# CTRL_MODULE_CORE register map
Vendor: Texas Instruments
Registers are 32-bit, access per field, reset 0x0 unless marked. A register's access mark holds for its fields unless they carry their own. Offsets are as the file gives them; [hi:lo] are bit positions; {n}, {i} and the like mark numbered series; 'fields as' and 'values as' point back to an identical list.

## CTRL_MODULE_CORE (part 2 of 5)
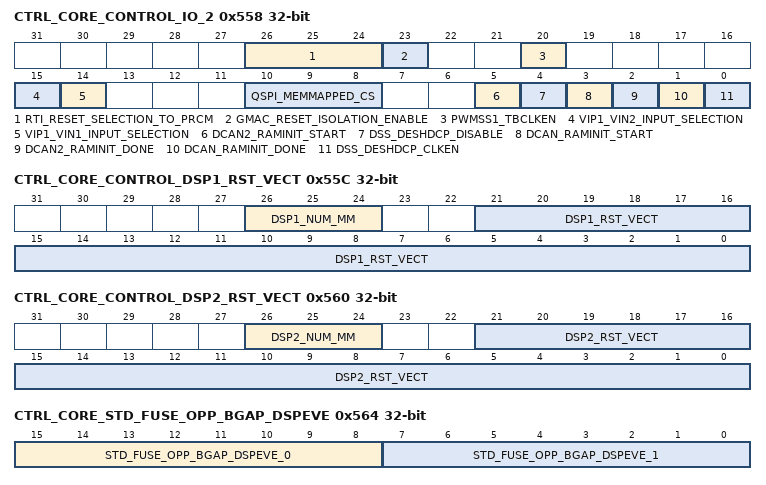
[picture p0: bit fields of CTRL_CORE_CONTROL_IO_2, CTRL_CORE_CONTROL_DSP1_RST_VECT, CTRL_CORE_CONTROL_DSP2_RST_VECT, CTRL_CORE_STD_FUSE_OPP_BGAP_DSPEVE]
0x558 CTRL_CORE_CONTROL_IO_2 — Register to configure some IP level signals
  [26:24] RTI_RESET_SELECTION_TO_PRCM rw — RTI reset mux select value. 0x0: RTI1 0x1: RTI2 0x2: RTI3 0x3: RTI4 0x4: RTI5
  [23] GMAC_RESET_ISOLATION_ENABLE rw — Reset isolation enable setting 0x0 = Reset is not isolated 0x1 = Reset is isolated
  [20] PWMSS1_TBCLKEN rw — PWMSS1 CLOCK ENABLE setting
  [15] VIP1_VIN2_INPUT_SELECTION rw — VIP1 vin2 input selection setting. 0x0: Input from pins selected. 0x1: Input from LVDSRX port2 selected.
  [14] VIP1_VIN1_INPUT_SELECTION rw — VIP1 vin1 input selection setting. 0x0: Input from pins selected. 0x1: Input from LVDSRX port1 selected.
  [10:8] QSPI_MEMMAPPED_CS rw — QSPI CS MAPPING setting. 0x0: The QSPI configuration registers are accessed 0x1: An external device connected to CS0 is accessed 0x2: An external device connected to CS1 is accessed 0x3: An external device connected to CS2 is accessed 0x4-0x7: An external device connected to CS3 is accessed
  [5] DCAN2_RAMINIT_START rw — DCAN2 RAM INIT START setting (SR1.0 Only). Reserved on SR2.0. To initialize DCAN2 RAM, the bit should be set to 0x1. It is not auto cleared by hardware. : If DCAN RAMINIT sequence needs to be redone, this bit should be first cleared and then set again.
  [4] DSS_DESHDCP_DISABLE rw — DSS DESHDCP DISABLE setting
  [3] DCAN_RAMINIT_START rw — DCAN RAM INIT START setting To initialize DCAN RAM, the bit should be set to 0x1. It is not auto cleared by hardware. : If DCAN RAMINIT sequence needs to be redone, this bit should be first cleared and then set again.: is called on SR1.0 devices.
  [2] DCAN2_RAMINIT_DONE rw — DCAN2 RAM INIT DONE status (SR1.0 Only). Reserved on SR2.0
  [1] DCAN_RAMINIT_DONE rw — DCAN RAM INIT DONE status: is called on SR1.0 devices.
  [0] DSS_DESHDCP_CLKEN rw — DSS DESHDCP CLOCK ENABLE setting
0x55C CTRL_CORE_CONTROL_DSP1_RST_VECT — Register for storing DSP1 reset vector
  [26:24] DSP1_NUM_MM rw — Number of DSP instances in the SoC 0x1 = 1 0x2 = 2
  [21:0] DSP1_RST_VECT rw — DSP1 reset vector address
0x560 CTRL_CORE_CONTROL_DSP2_RST_VECT — Register for storing DSP2 reset vector
  [26:24] DSP2_NUM_MM rw — Number of DSP instances in the SoC 0x1 = 1 0x2 = 2
  [21:0] DSP2_RST_VECT rw — DSP2 reset vector address
0x564 CTRL_CORE_STD_FUSE_OPP_BGAP_DSPEVE ro reset not defined — Trim values for DSPEVE associated bandgap. Contains TI Internal information, not intended for application use.
  [15:8] STD_FUSE_OPP_BGAP_DSPEVE_0 — Trim values for DSPEVE associated bandgap. Contains TI Internal information, not intended for application use.
  [7:0] STD_FUSE_OPP_BGAP_DSPEVE_1 — Trim values for DSPEVE associated bandgap. Contains TI Internal information, not intended for application use.
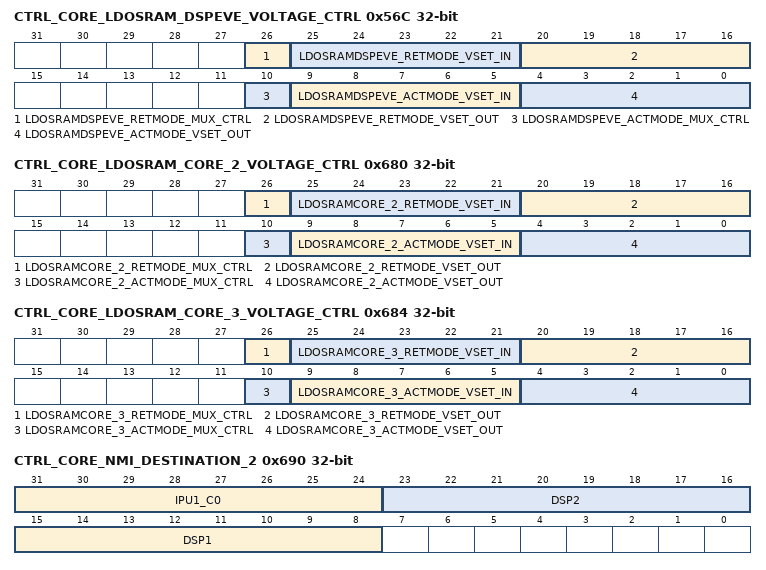
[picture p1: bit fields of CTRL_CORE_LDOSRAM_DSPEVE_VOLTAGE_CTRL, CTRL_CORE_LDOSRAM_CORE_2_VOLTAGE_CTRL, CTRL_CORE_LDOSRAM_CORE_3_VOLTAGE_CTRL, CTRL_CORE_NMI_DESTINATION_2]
0x56C CTRL_CORE_LDOSRAM_DSPEVE_VOLTAGE_CTRL — DSPEVE SRAM LDO Control register
  [26] LDOSRAMDSPEVE_RETMODE_MUX_CTRL rw — Override control of EFUSE Retention Mode Voltage value
    0=EFUSE (eFuse value is used); 1=OCP (Override value is used)
  [25:21] LDOSRAMDSPEVE_RETMODE_VSET_IN ro — EFUSE Retention Mode Voltage value (vset[9:5])
  [20:16] LDOSRAMDSPEVE_RETMODE_VSET_OUT rw — Override value for Retention Mode Voltage
  [10] LDOSRAMDSPEVE_ACTMODE_MUX_CTRL rw — Override control of EFUSE Active Mode Voltage value
    values as LDOSRAMDSPEVE_RETMODE_MUX_CTRL
  [9:5] LDOSRAMDSPEVE_ACTMODE_VSET_IN ro — EFUSE Active Mode Voltage value (vset[4:0])
  [4:0] LDOSRAMDSPEVE_ACTMODE_VSET_OUT rw — Override value for Active Mode Voltage value
0x5E0 CTRL_CORE_STD_FUSE_OPP_VMIN_DSPEVE_2 ro reset not defined — This register contains the AVS Class 0 voltage value for the vdd_dspeve voltage rail when running at OPP_NOM.
  [11:0] STD_FUSE_OPP_VMIN_DSPEVE_2 — AVS Class 0 voltage value for the vdd_dspeve voltage rail when running at OPP_NOM. To get the actual value in mV, the value read from this bit field must be converted to decimal value.
0x5E4 CTRL_CORE_STD_FUSE_OPP_VMIN_DSPEVE_3 ro reset not defined — This register contains the AVS Class 0 voltage value for the vdd_dspeve voltage rail when running at OPP_OD.
  [11:0] STD_FUSE_OPP_VMIN_DSPEVE_3 — AVS Class 0 voltage value for the vdd_dspeve voltage rail when running at OPP_OD. To get the actual value in mV, the value read from this bit field must be converted to decimal value.
0x5E8 CTRL_CORE_STD_FUSE_OPP_VMIN_DSPEVE_4 ro reset not defined — This register contains the AVS Class 0 voltage value for the vdd_dspeve voltage rail when running at OPP_HIGH.
  [11:0] STD_FUSE_OPP_VMIN_DSPEVE_4 — AVS Class 0 voltage value for the vdd_dspeve voltage rail when running at OPP_HIGH. To get the actual value in mV, the value read from this bit field must be converted to decimal value.
0x5EC CTRL_CORE_RC_OSC_FREQUENCY ro reset not defined — This register is used only on SR2.0 devices.
  [25:0] RC_OSC_CALIBRATION_VALUE — Used only on SR2.0 devices.
0x5F4 CTRL_CORE_STD_FUSE_OPP_VMIN_CORE_2 ro reset not defined — This register contains the AVS Class 0 voltage value for the vdd voltage rail when running at OPP_NOM.
  [11:0] STD_FUSE_OPP_VMIN_CORE_2 — AVS Class 0 voltage value for the vdd voltage rail when running at OPP_NOM. To get the actual value in mV, the value read from this bit field must be converted to decimal value.
0x680 CTRL_CORE_LDOSRAM_CORE_2_VOLTAGE_CTRL — CORE 2nd SRAM LDO Control register
  [26] LDOSRAMCORE_2_RETMODE_MUX_CTRL rw — Override control of EFUSE Retention Mode Voltage value
    values as CTRL_CORE_LDOSRAM_DSPEVE_VOLTAGE_CTRL.LDOSRAMDSPEVE_RETMODE_MUX_CTRL
  [25:21] LDOSRAMCORE_2_RETMODE_VSET_IN ro — EFUSE Retention Mode Voltage value (vset[9:5])
  [20:16] LDOSRAMCORE_2_RETMODE_VSET_OUT rw — Override value for Retention Mode Voltage
  [10] LDOSRAMCORE_2_ACTMODE_MUX_CTRL rw — Override control of EFUSE Active Mode Voltage value
    values as CTRL_CORE_LDOSRAM_DSPEVE_VOLTAGE_CTRL.LDOSRAMDSPEVE_RETMODE_MUX_CTRL
  [9:5] LDOSRAMCORE_2_ACTMODE_VSET_IN ro — EFUSE Active Mode Voltage value (vset[4:0])
  [4:0] LDOSRAMCORE_2_ACTMODE_VSET_OUT rw — Override value for Active Mode Voltage value
0x684 CTRL_CORE_LDOSRAM_CORE_3_VOLTAGE_CTRL — CORE 3rd SRAM LDO Control register
  [26] LDOSRAMCORE_3_RETMODE_MUX_CTRL rw — Override control of EFUSE Retention Mode Voltage value
    values as CTRL_CORE_LDOSRAM_DSPEVE_VOLTAGE_CTRL.LDOSRAMDSPEVE_RETMODE_MUX_CTRL
  [25:21] LDOSRAMCORE_3_RETMODE_VSET_IN ro — EFUSE Retention Mode Voltage value (vset[9:5])
  [20:16] LDOSRAMCORE_3_RETMODE_VSET_OUT rw — Override value for Retention Mode Voltage
  [10] LDOSRAMCORE_3_ACTMODE_MUX_CTRL rw — Override control of EFUSE Active Mode Voltage value
    values as CTRL_CORE_LDOSRAM_DSPEVE_VOLTAGE_CTRL.LDOSRAMDSPEVE_RETMODE_MUX_CTRL
  [9:5] LDOSRAMCORE_3_ACTMODE_VSET_IN ro — EFUSE Active Mode Voltage value (vset[4:0])
  [4:0] LDOSRAMCORE_3_ACTMODE_VSET_OUT rw — Override value for Active Mode Voltage value
0x68C CTRL_CORE_NMI_DESTINATION_1 rw — Register for routing NMI interrupt to respective cores
  [7:0] IPU1_C1 — Enable IPU1 CORE1 to receive the NMI interrupt 0x0 = NMI disabled 0x1 = NMI enabled
0x690 CTRL_CORE_NMI_DESTINATION_2 — Register for routing NMI interrupt to respective cores
  [31:24] IPU1_C0 rw — Enable IPU1 CORE0 to receive the NMI interrupt 0x0 = NMI disabled 0x1 = NMI enabled
  [23:16] DSP2 rw — Enable DSP2 to receive the NMI interrupt 0x0 = NMI disabled 0x1 = NMI enabled
  [15:8] DSP1 rw — Enable DSP1 to receive the NMI interrupt 0x0 = NMI disabled 0x1 = NMI enabled
{0x6A0+4i} CTRL_CORE_STD_FUSE_OPP_VDD_DSPEVE_{i} ro (i=0..4) — Standard Fuse OPP VDD_DSPEVE [{32i+31}:{32i}]. Register shows part of the chip eFuse configuration on the OCP interface. Reading at the address of one of these registers provides a direct view into a part of the eFuse chain.
  [31:0] STD_FUSE_OPP_VDD_DSPEVE_{i}
0x6B4 CTRL_CORE_CUST_FUSE_SWRV_7 ro — Customer Fuse keys. SWRV [31:0] (16 bits upper Redundant field) [FIELD A]. Register shows part of the chip eFuse configuration on the OCP interface. Reading at the address of one of these registers provides a direct view into a part of the eFuse chain.
  [31:0] CUST_FUSE_SWRV_7
0x6B8 CTRL_CORE_STD_FUSE_CALIBRATION_OVERRIDE_VALUE_0 ro — Standard Fuse Calibration override value [31:0]. Register shows part of the chip eFuse configuration on the OCP interface. Reading at the address of one of these registers provides a direct view into a part of the eFuse chain.
  [31:0] STD_FUSE_CALIBRATION_OVERRIDE_VALUE_0
0x6BC CTRL_CORE_STD_FUSE_CALIBRATION_OVERRIDE_VALUE_1 ro — Standard Fuse Calibration override value [63:32]. Register shows part of the chip eFuse configuration on the OCP interface. Reading at the address of one of these registers provides a direct view into a part of the eFuse chain.
  [31:0] STD_FUSE_CALIBRATION_OVERRIDE_VALUE_1
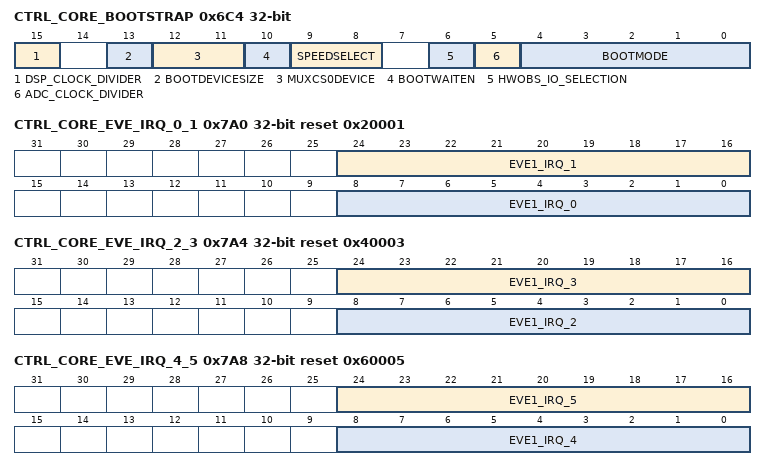
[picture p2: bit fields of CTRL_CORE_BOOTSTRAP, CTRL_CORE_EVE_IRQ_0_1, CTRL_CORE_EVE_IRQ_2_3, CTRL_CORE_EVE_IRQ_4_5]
0x6C4 CTRL_CORE_BOOTSTRAP ro — Register to view all the sysboot settings
  [15] DSP_CLOCK_DIVIDER — Divide factor for DSP clock
  [13] BOOTDEVICESIZE — Select the size of the flash device on CS0. 0x0: 8-bit 0x1: 16-bit
  [12:11] MUXCS0DEVICE — Select IC boot sequence to be executed from a multiplexed address and data device attached to CS0. 0x0: Non-muxed device attached 0x1: Addr-Data Mux device attached 0x2: Reserved 0x3: Reserved
  [10] BOOTWAITEN — Enable the monitoring on CS0 of the wait pin at IC reset release time for read accesses. 0x0: Wait pin is not monitored for read accesses 0x1: Wait pin is monitored for read accesses
  [9:8] SPEEDSELECT — Indicates the SYS_CLK1 frequency (from osc0). Note that the internal FUNC_32K_CLK is equal to SYS_CLK1/610, which is nominally 32.7869 kHz with 20 MHz clock. 0x0: Reserved 0x1: 20 MHz 0x2: 27 MHz 0x3: 19.2 MHz
  [6] HWOBS_IO_SELECTION
  [5] ADC_CLOCK_DIVIDER
  [4:0] BOOTMODE — SYSBOOT mode
0x794 CTRL_CORE_SEC_ERR_STATUS_FUNC_3 access not given
  [0] CRC_FW_ERROR — CRC firewall (access RW W1toClr)
    0=NO_EDMA_TC1_FW_ERROR (No error from firewall); 1=EDMA_TC1_FW_ERROR (Error from firewall)
0x79C CTRL_CORE_SEC_ERR_STATUS_DEBUG_3 access not given — Security Error Status functional Register
  [0] CRC_DBGFW_ERROR — CRC debug firewall (access RW W1toClr)
    values as CTRL_CORE_SEC_ERR_STATUS_FUNC_3.CRC_FW_ERROR
0x7A0 CTRL_CORE_EVE_IRQ_0_1 reset 0x20001
  [24:16] EVE1_IRQ_1 rw, [8:0] EVE1_IRQ_0 rw
0x7A4 CTRL_CORE_EVE_IRQ_2_3 reset 0x40003
  [24:16] EVE1_IRQ_3 rw, [8:0] EVE1_IRQ_2 rw
0x7A8 CTRL_CORE_EVE_IRQ_4_5 reset 0x60005
  [24:16] EVE1_IRQ_5 rw, [8:0] EVE1_IRQ_4 rw
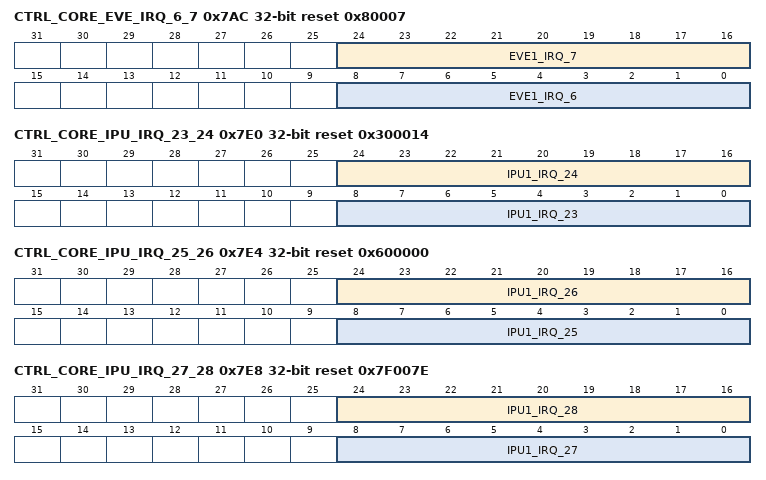
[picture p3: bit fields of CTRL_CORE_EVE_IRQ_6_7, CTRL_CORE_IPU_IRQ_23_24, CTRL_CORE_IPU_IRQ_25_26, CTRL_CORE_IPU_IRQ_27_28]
0x7AC CTRL_CORE_EVE_IRQ_6_7 reset 0x80007
  [24:16] EVE1_IRQ_7 rw, [8:0] EVE1_IRQ_6 rw
0x7E0 CTRL_CORE_IPU_IRQ_23_24 reset 0x300014
  [24:16] IPU1_IRQ_24 rw, [8:0] IPU1_IRQ_23 rw
0x7E4 CTRL_CORE_IPU_IRQ_25_26 reset 0x600000
  [24:16] IPU1_IRQ_26 rw, [8:0] IPU1_IRQ_25 rw
0x7E8 CTRL_CORE_IPU_IRQ_27_28 reset 0x7F007E
  [24:16] IPU1_IRQ_28 rw, [8:0] IPU1_IRQ_27 rw
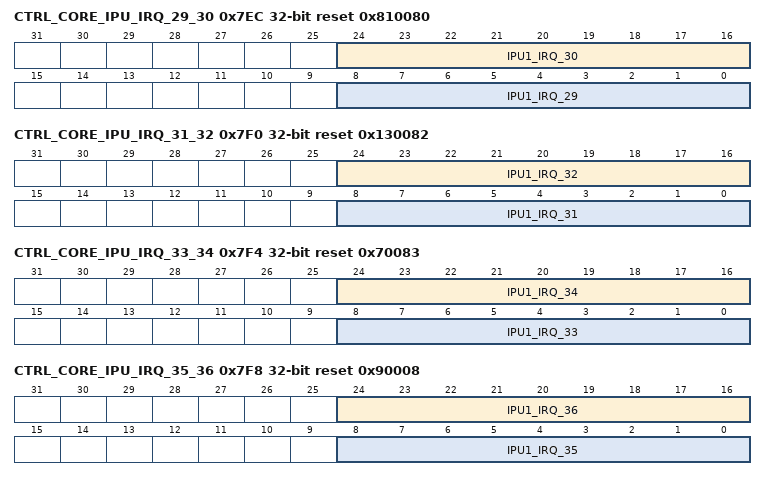
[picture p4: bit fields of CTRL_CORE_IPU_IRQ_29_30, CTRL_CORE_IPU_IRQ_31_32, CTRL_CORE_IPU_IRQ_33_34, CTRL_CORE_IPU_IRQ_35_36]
0x7EC CTRL_CORE_IPU_IRQ_29_30 reset 0x810080
  [24:16] IPU1_IRQ_30 rw, [8:0] IPU1_IRQ_29 rw
0x7F0 CTRL_CORE_IPU_IRQ_31_32 reset 0x130082
  [24:16] IPU1_IRQ_32 rw, [8:0] IPU1_IRQ_31 rw
0x7F4 CTRL_CORE_IPU_IRQ_33_34 reset 0x70083
  [24:16] IPU1_IRQ_34 rw, [8:0] IPU1_IRQ_33 rw
0x7F8 CTRL_CORE_IPU_IRQ_35_36 reset 0x90008
  [24:16] IPU1_IRQ_36 rw, [8:0] IPU1_IRQ_35 rw
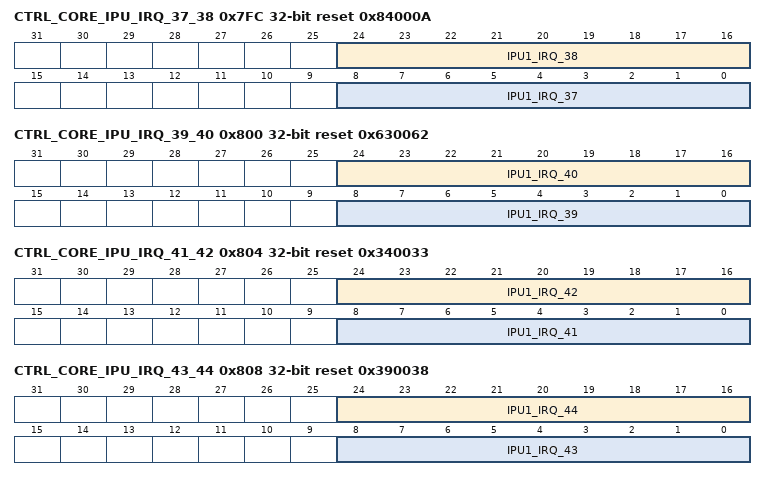
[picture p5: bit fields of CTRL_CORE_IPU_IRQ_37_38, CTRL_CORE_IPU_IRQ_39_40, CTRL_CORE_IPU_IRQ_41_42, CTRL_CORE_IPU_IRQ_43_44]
0x7FC CTRL_CORE_IPU_IRQ_37_38 reset 0x84000A
  [24:16] IPU1_IRQ_38 rw, [8:0] IPU1_IRQ_37 rw
0x800 CTRL_CORE_IPU_IRQ_39_40 reset 0x630062
  [24:16] IPU1_IRQ_40 rw, [8:0] IPU1_IRQ_39 rw
0x804 CTRL_CORE_IPU_IRQ_41_42 reset 0x340033
  [24:16] IPU1_IRQ_42 rw, [8:0] IPU1_IRQ_41 rw
0x808 CTRL_CORE_IPU_IRQ_43_44 reset 0x390038
  [24:16] IPU1_IRQ_44 rw, [8:0] IPU1_IRQ_43 rw
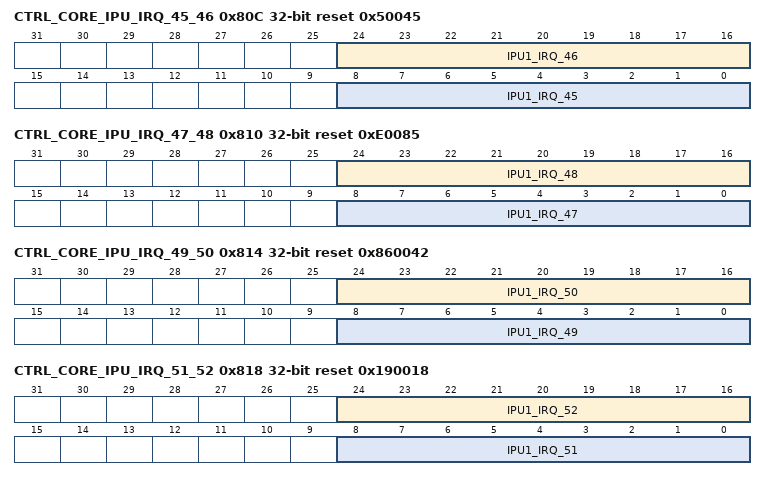
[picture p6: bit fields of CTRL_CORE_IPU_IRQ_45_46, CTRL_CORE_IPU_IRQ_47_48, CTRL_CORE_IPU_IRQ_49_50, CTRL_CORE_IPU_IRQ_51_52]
0x80C CTRL_CORE_IPU_IRQ_45_46 reset 0x50045
  [24:16] IPU1_IRQ_46 rw, [8:0] IPU1_IRQ_45 rw
0x810 CTRL_CORE_IPU_IRQ_47_48 reset 0xE0085
  [24:16] IPU1_IRQ_48 rw, [8:0] IPU1_IRQ_47 rw
0x814 CTRL_CORE_IPU_IRQ_49_50 reset 0x860042
  [24:16] IPU1_IRQ_50 rw, [8:0] IPU1_IRQ_49 rw
0x818 CTRL_CORE_IPU_IRQ_51_52 reset 0x190018
  [24:16] IPU1_IRQ_52 rw, [8:0] IPU1_IRQ_51 rw
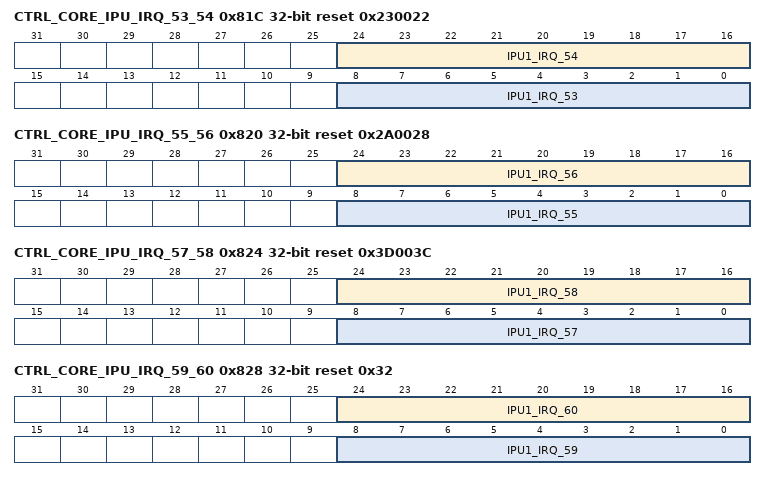
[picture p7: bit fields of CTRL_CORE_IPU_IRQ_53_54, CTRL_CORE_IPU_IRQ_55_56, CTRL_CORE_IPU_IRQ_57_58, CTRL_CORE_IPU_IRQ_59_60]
0x81C CTRL_CORE_IPU_IRQ_53_54 reset 0x230022
  [24:16] IPU1_IRQ_54 rw, [8:0] IPU1_IRQ_53 rw
0x820 CTRL_CORE_IPU_IRQ_55_56 reset 0x2A0028
  [24:16] IPU1_IRQ_56 rw, [8:0] IPU1_IRQ_55 rw
0x824 CTRL_CORE_IPU_IRQ_57_58 reset 0x3D003C
  [24:16] IPU1_IRQ_58 rw, [8:0] IPU1_IRQ_57 rw
0x828 CTRL_CORE_IPU_IRQ_59_60 reset 0x32
  [24:16] IPU1_IRQ_60 rw, [8:0] IPU1_IRQ_59 rw
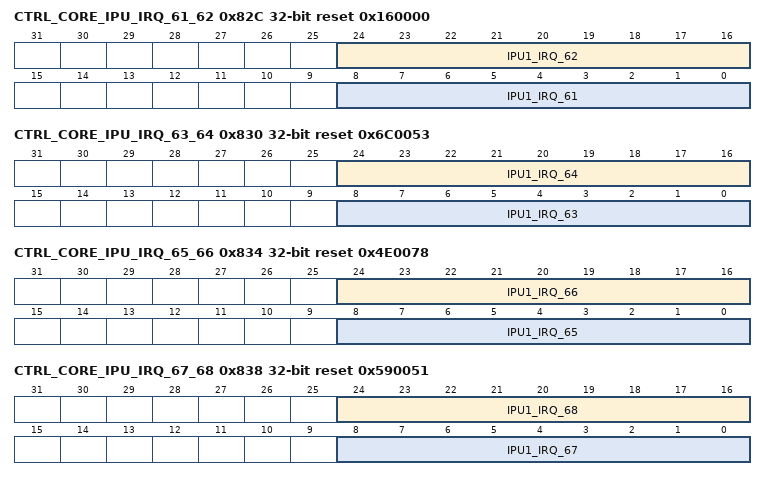
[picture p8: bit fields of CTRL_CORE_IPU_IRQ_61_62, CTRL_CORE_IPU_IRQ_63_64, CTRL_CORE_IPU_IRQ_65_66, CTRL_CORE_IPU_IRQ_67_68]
0x82C CTRL_CORE_IPU_IRQ_61_62 reset 0x160000
  [24:16] IPU1_IRQ_62 rw, [8:0] IPU1_IRQ_61 rw
0x830 CTRL_CORE_IPU_IRQ_63_64 reset 0x6C0053
  [24:16] IPU1_IRQ_64 rw, [8:0] IPU1_IRQ_63 rw
0x834 CTRL_CORE_IPU_IRQ_65_66 reset 0x4E0078
  [24:16] IPU1_IRQ_66 rw, [8:0] IPU1_IRQ_65 rw
0x838 CTRL_CORE_IPU_IRQ_67_68 reset 0x590051
  [24:16] IPU1_IRQ_68 rw, [8:0] IPU1_IRQ_67 rw
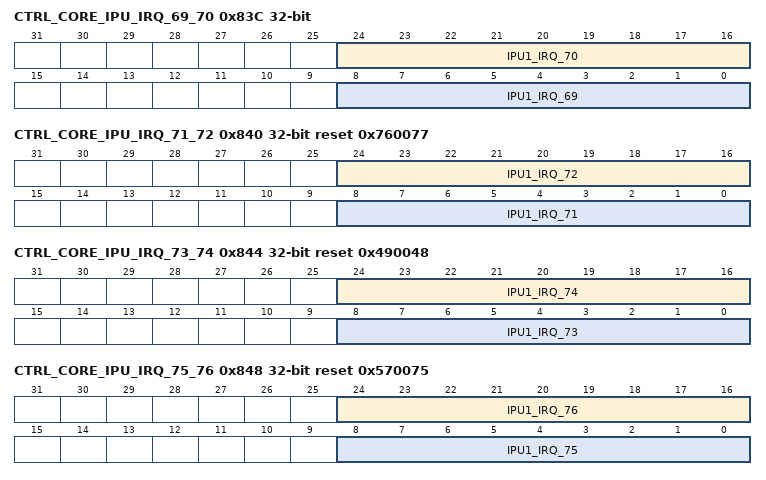
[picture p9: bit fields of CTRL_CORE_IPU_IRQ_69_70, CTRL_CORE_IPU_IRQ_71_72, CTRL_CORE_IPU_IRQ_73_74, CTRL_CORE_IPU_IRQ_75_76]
0x83C CTRL_CORE_IPU_IRQ_69_70
  [24:16] IPU1_IRQ_70 rw, [8:0] IPU1_IRQ_69 rw
0x840 CTRL_CORE_IPU_IRQ_71_72 reset 0x760077
  [24:16] IPU1_IRQ_72 rw, [8:0] IPU1_IRQ_71 rw
0x844 CTRL_CORE_IPU_IRQ_73_74 reset 0x490048
  [24:16] IPU1_IRQ_74 rw, [8:0] IPU1_IRQ_73 rw
0x848 CTRL_CORE_IPU_IRQ_75_76 reset 0x570075
  [24:16] IPU1_IRQ_76 rw, [8:0] IPU1_IRQ_75 rw
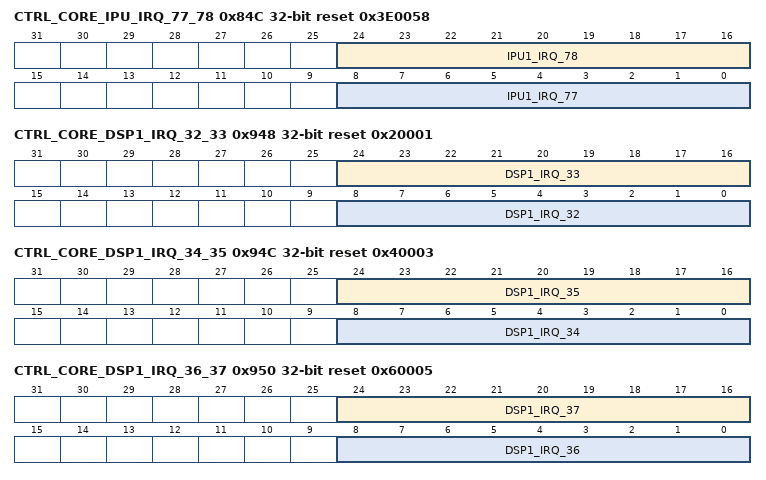
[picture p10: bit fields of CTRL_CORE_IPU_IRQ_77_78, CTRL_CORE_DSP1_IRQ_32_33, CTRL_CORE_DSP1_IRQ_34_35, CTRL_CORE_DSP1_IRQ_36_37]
0x84C CTRL_CORE_IPU_IRQ_77_78 reset 0x3E0058
  [24:16] IPU1_IRQ_78 rw, [8:0] IPU1_IRQ_77 rw
0x850 CTRL_CORE_IPU_IRQ_79_80 reset 0x3F
  [8:0] IPU1_IRQ_79 rw
0x948 CTRL_CORE_DSP1_IRQ_32_33 reset 0x20001
  [24:16] DSP1_IRQ_33 rw, [8:0] DSP1_IRQ_32 rw
0x94C CTRL_CORE_DSP1_IRQ_34_35 reset 0x40003
  [24:16] DSP1_IRQ_35 rw, [8:0] DSP1_IRQ_34 rw
0x950 CTRL_CORE_DSP1_IRQ_36_37 reset 0x60005
  [24:16] DSP1_IRQ_37 rw, [8:0] DSP1_IRQ_36 rw
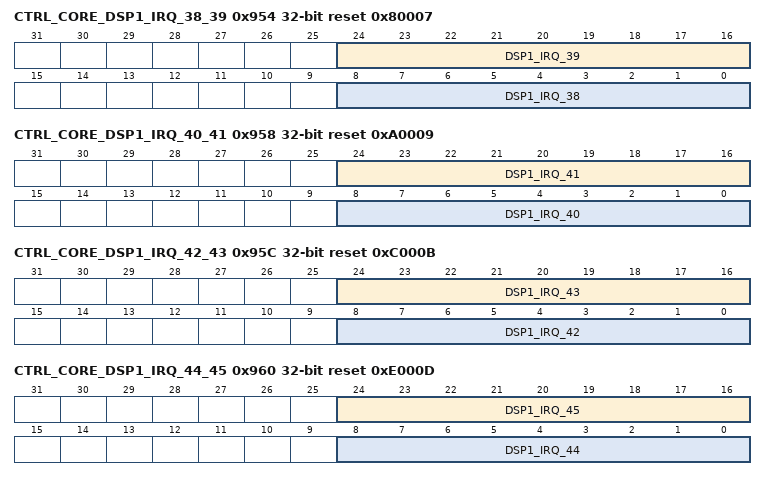
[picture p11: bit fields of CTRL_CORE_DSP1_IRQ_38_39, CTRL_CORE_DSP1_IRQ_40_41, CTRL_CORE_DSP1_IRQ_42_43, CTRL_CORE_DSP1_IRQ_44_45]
0x954 CTRL_CORE_DSP1_IRQ_38_39 reset 0x80007
  [24:16] DSP1_IRQ_39 rw, [8:0] DSP1_IRQ_38 rw
0x958 CTRL_CORE_DSP1_IRQ_40_41 reset 0xA0009
  [24:16] DSP1_IRQ_41 rw, [8:0] DSP1_IRQ_40 rw
0x95C CTRL_CORE_DSP1_IRQ_42_43 reset 0xC000B
  [24:16] DSP1_IRQ_43 rw, [8:0] DSP1_IRQ_42 rw
0x960 CTRL_CORE_DSP1_IRQ_44_45 reset 0xE000D
  [24:16] DSP1_IRQ_45 rw, [8:0] DSP1_IRQ_44 rw
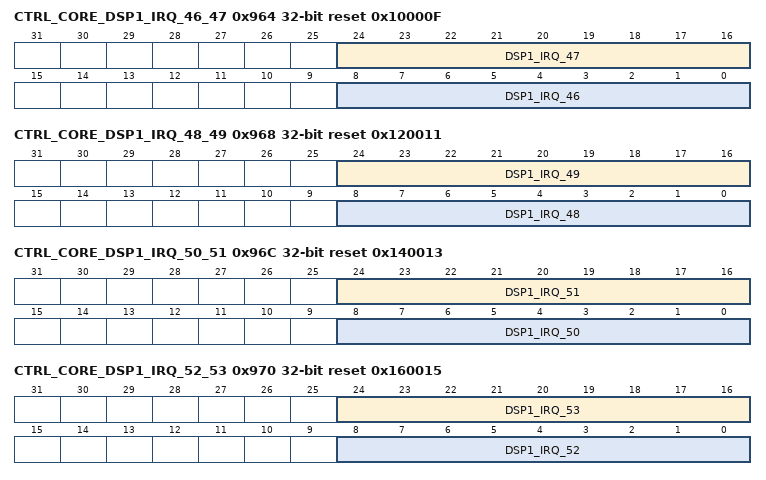
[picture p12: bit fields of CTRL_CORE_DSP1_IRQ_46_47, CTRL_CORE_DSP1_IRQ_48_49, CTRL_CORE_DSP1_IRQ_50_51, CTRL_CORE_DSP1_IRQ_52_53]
0x964 CTRL_CORE_DSP1_IRQ_46_47 reset 0x10000F
  [24:16] DSP1_IRQ_47 rw, [8:0] DSP1_IRQ_46 rw
0x968 CTRL_CORE_DSP1_IRQ_48_49 reset 0x120011
  [24:16] DSP1_IRQ_49 rw, [8:0] DSP1_IRQ_48 rw
0x96C CTRL_CORE_DSP1_IRQ_50_51 reset 0x140013
  [24:16] DSP1_IRQ_51 rw, [8:0] DSP1_IRQ_50 rw
0x970 CTRL_CORE_DSP1_IRQ_52_53 reset 0x160015
  [24:16] DSP1_IRQ_53 rw, [8:0] DSP1_IRQ_52 rw
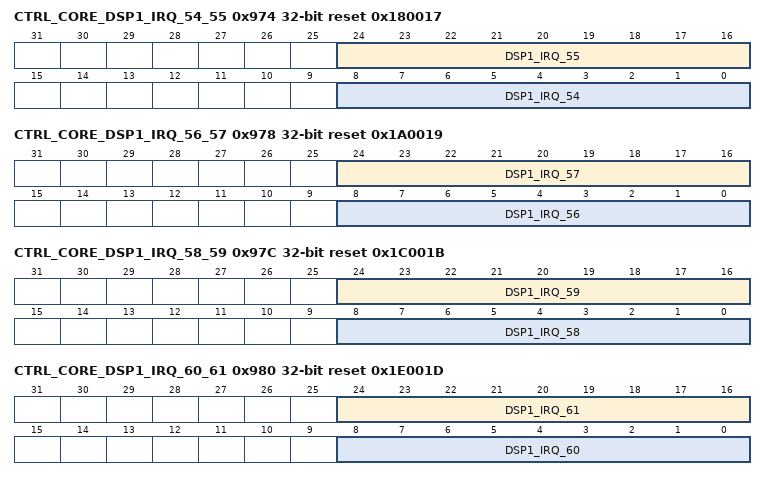
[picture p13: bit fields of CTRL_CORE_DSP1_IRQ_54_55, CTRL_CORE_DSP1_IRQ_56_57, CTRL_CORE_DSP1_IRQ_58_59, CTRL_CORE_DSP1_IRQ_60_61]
0x974 CTRL_CORE_DSP1_IRQ_54_55 reset 0x180017
  [24:16] DSP1_IRQ_55 rw, [8:0] DSP1_IRQ_54 rw
0x978 CTRL_CORE_DSP1_IRQ_56_57 reset 0x1A0019
  [24:16] DSP1_IRQ_57 rw, [8:0] DSP1_IRQ_56 rw
0x97C CTRL_CORE_DSP1_IRQ_58_59 reset 0x1C001B
  [24:16] DSP1_IRQ_59 rw, [8:0] DSP1_IRQ_58 rw
0x980 CTRL_CORE_DSP1_IRQ_60_61 reset 0x1E001D
  [24:16] DSP1_IRQ_61 rw, [8:0] DSP1_IRQ_60 rw
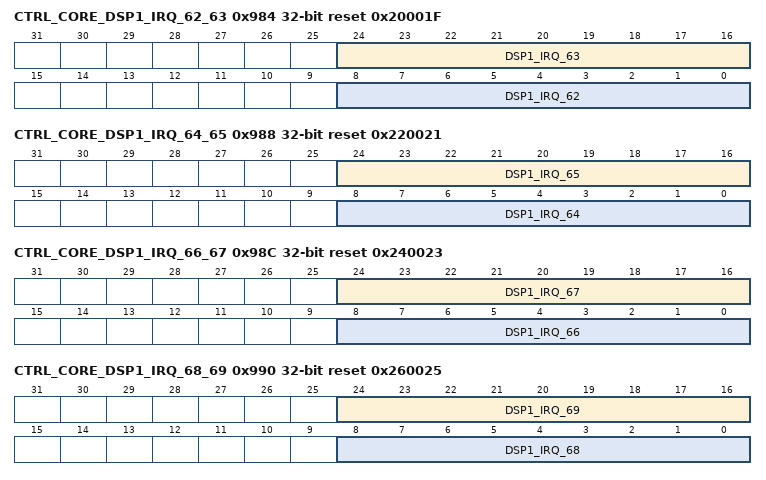
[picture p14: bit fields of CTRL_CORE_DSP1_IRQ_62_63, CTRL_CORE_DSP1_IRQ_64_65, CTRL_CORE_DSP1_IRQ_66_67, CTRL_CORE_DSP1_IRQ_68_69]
0x984 CTRL_CORE_DSP1_IRQ_62_63 reset 0x20001F
  [24:16] DSP1_IRQ_63 rw, [8:0] DSP1_IRQ_62 rw
0x988 CTRL_CORE_DSP1_IRQ_64_65 reset 0x220021
  [24:16] DSP1_IRQ_65 rw, [8:0] DSP1_IRQ_64 rw
0x98C CTRL_CORE_DSP1_IRQ_66_67 reset 0x240023
  [24:16] DSP1_IRQ_67 rw, [8:0] DSP1_IRQ_66 rw
0x990 CTRL_CORE_DSP1_IRQ_68_69 reset 0x260025
  [24:16] DSP1_IRQ_69 rw, [8:0] DSP1_IRQ_68 rw
0x994 CTRL_CORE_DSP1_IRQ_70_71 reset 0x280027
  [24:16] DSP1_IRQ_71 rw, [8:0] DSP1_IRQ_70 rw
0x998 CTRL_CORE_DSP1_IRQ_72_73 reset 0x2A0029
  [24:16] DSP1_IRQ_73 rw, [8:0] DSP1_IRQ_72 rw
0x99C CTRL_CORE_DSP1_IRQ_74_75 reset 0x2C002B
  [24:16] DSP1_IRQ_75 rw, [8:0] DSP1_IRQ_74 rw
0x9A0 CTRL_CORE_DSP1_IRQ_76_77 reset 0x2E002D
  [24:16] DSP1_IRQ_77 rw, [8:0] DSP1_IRQ_76 rw
0x9A4 CTRL_CORE_DSP1_IRQ_78_79 reset 0x30002F
  [24:16] DSP1_IRQ_79 rw, [8:0] DSP1_IRQ_78 rw
0x9A8 CTRL_CORE_DSP1_IRQ_80_81 reset 0x320031
  [24:16] DSP1_IRQ_81 rw, [8:0] DSP1_IRQ_80 rw
0x9AC CTRL_CORE_DSP1_IRQ_82_83 reset 0x340033
  [24:16] DSP1_IRQ_83 rw, [8:0] DSP1_IRQ_82 rw
0x9B0 CTRL_CORE_DSP1_IRQ_84_85 reset 0x360035
  [24:16] DSP1_IRQ_85 rw, [8:0] DSP1_IRQ_84 rw
0x9B4 CTRL_CORE_DSP1_IRQ_86_87 reset 0x380037
  [24:16] DSP1_IRQ_87 rw, [8:0] DSP1_IRQ_86 rw
0x9B8 CTRL_CORE_DSP1_IRQ_88_89 reset 0x3A0039
  [24:16] DSP1_IRQ_89 rw, [8:0] DSP1_IRQ_88 rw
0x9BC CTRL_CORE_DSP1_IRQ_90_91 reset 0x3C003B
  [24:16] DSP1_IRQ_91 rw, [8:0] DSP1_IRQ_90 rw
0x9C0 CTRL_CORE_DSP1_IRQ_92_93 reset 0x3E003D
  [24:16] DSP1_IRQ_93 rw, [8:0] DSP1_IRQ_92 rw
0x9C4 CTRL_CORE_DSP1_IRQ_94_95 reset 0x40003F
  [24:16] DSP1_IRQ_95 rw, [8:0] DSP1_IRQ_94 rw
0x9C8 CTRL_CORE_DSP2_IRQ_32_33 reset 0x20001
  [24:16] DSP2_IRQ_33 rw, [8:0] DSP2_IRQ_32 rw
0x9CC CTRL_CORE_DSP2_IRQ_34_35 reset 0x40003
  [24:16] DSP2_IRQ_35 rw, [8:0] DSP2_IRQ_34 rw
0x9D0 CTRL_CORE_DSP2_IRQ_36_37 reset 0x60005
  [24:16] DSP2_IRQ_37 rw, [8:0] DSP2_IRQ_36 rw
0x9D4 CTRL_CORE_DSP2_IRQ_38_39 reset 0x80007
  [24:16] DSP2_IRQ_39 rw, [8:0] DSP2_IRQ_38 rw
0x9D8 CTRL_CORE_DSP2_IRQ_40_41 reset 0xA0009
  [24:16] DSP2_IRQ_41 rw, [8:0] DSP2_IRQ_40 rw
0x9DC CTRL_CORE_DSP2_IRQ_42_43 reset 0xC000B
  [24:16] DSP2_IRQ_43 rw, [8:0] DSP2_IRQ_42 rw
0x9E0 CTRL_CORE_DSP2_IRQ_44_45 reset 0xE000D
  [24:16] DSP2_IRQ_45 rw, [8:0] DSP2_IRQ_44 rw
0x9E4 CTRL_CORE_DSP2_IRQ_46_47 reset 0x10000F
  [24:16] DSP2_IRQ_47 rw, [8:0] DSP2_IRQ_46 rw
0x9E8 CTRL_CORE_DSP2_IRQ_48_49 reset 0x120011
  [24:16] DSP2_IRQ_49 rw, [8:0] DSP2_IRQ_48 rw
0x9EC CTRL_CORE_DSP2_IRQ_50_51 reset 0x140013
  [24:16] DSP2_IRQ_51 rw, [8:0] DSP2_IRQ_50 rw
0x9F0 CTRL_CORE_DSP2_IRQ_52_53 reset 0x160015
  [24:16] DSP2_IRQ_53 rw, [8:0] DSP2_IRQ_52 rw
0x9F4 CTRL_CORE_DSP2_IRQ_54_55 reset 0x180017
  [24:16] DSP2_IRQ_55 rw, [8:0] DSP2_IRQ_54 rw
0x9F8 CTRL_CORE_DSP2_IRQ_56_57 reset 0x1A0019
  [24:16] DSP2_IRQ_57 rw, [8:0] DSP2_IRQ_56 rw
0x9FC CTRL_CORE_DSP2_IRQ_58_59 reset 0x1C001B
  [24:16] DSP2_IRQ_59 rw, [8:0] DSP2_IRQ_58 rw
0xA00 CTRL_CORE_DSP2_IRQ_60_61 reset 0x1E001D
  [24:16] DSP2_IRQ_61 rw, [8:0] DSP2_IRQ_60 rw
0xA04 CTRL_CORE_DSP2_IRQ_62_63 reset 0x20001F
  [24:16] DSP2_IRQ_63 rw, [8:0] DSP2_IRQ_62 rw
0xA08 CTRL_CORE_DSP2_IRQ_64_65 reset 0x220021
  [24:16] DSP2_IRQ_65 rw, [8:0] DSP2_IRQ_64 rw
0xA0C CTRL_CORE_DSP2_IRQ_66_67 reset 0x240023
  [24:16] DSP2_IRQ_67 rw, [8:0] DSP2_IRQ_66 rw
0xA10 CTRL_CORE_DSP2_IRQ_68_69 reset 0x260025
  [24:16] DSP2_IRQ_69 rw, [8:0] DSP2_IRQ_68 rw
0xA14 CTRL_CORE_DSP2_IRQ_70_71 reset 0x280027
  [24:16] DSP2_IRQ_71 rw, [8:0] DSP2_IRQ_70 rw
0xA18 CTRL_CORE_DSP2_IRQ_72_73 reset 0x2A0029
  [24:16] DSP2_IRQ_73 rw, [8:0] DSP2_IRQ_72 rw
0xA1C CTRL_CORE_DSP2_IRQ_74_75 reset 0x2C002B
  [24:16] DSP2_IRQ_75 rw, [8:0] DSP2_IRQ_74 rw
0xA20 CTRL_CORE_DSP2_IRQ_76_77 reset 0x2E002D
  [24:16] DSP2_IRQ_77 rw, [8:0] DSP2_IRQ_76 rw
0xA24 CTRL_CORE_DSP2_IRQ_78_79 reset 0x30002F
  [24:16] DSP2_IRQ_79 rw, [8:0] DSP2_IRQ_78 rw
0xA28 CTRL_CORE_DSP2_IRQ_80_81 reset 0x320031
  [24:16] DSP2_IRQ_81 rw, [8:0] DSP2_IRQ_80 rw
0xA2C CTRL_CORE_DSP2_IRQ_82_83 reset 0x340033
  [24:16] DSP2_IRQ_83 rw, [8:0] DSP2_IRQ_82 rw
0xA30 CTRL_CORE_DSP2_IRQ_84_85 reset 0x360035
  [24:16] DSP2_IRQ_85 rw, [8:0] DSP2_IRQ_84 rw
0xA34 CTRL_CORE_DSP2_IRQ_86_87 reset 0x380037
  [24:16] DSP2_IRQ_87 rw, [8:0] DSP2_IRQ_86 rw
0xA38 CTRL_CORE_DSP2_IRQ_88_89 reset 0x3A0039
  [24:16] DSP2_IRQ_89 rw, [8:0] DSP2_IRQ_88 rw
0xA3C CTRL_CORE_DSP2_IRQ_90_91 reset 0x3C003B
  [24:16] DSP2_IRQ_91 rw, [8:0] DSP2_IRQ_90 rw
0xA40 CTRL_CORE_DSP2_IRQ_92_93 reset 0x3E003D
  [24:16] DSP2_IRQ_93 rw, [8:0] DSP2_IRQ_92 rw
0xA44 CTRL_CORE_DSP2_IRQ_94_95 reset 0x40003F
  [24:16] DSP2_IRQ_95 rw, [8:0] DSP2_IRQ_94 rw
0xC78 CTRL_CORE_DMA_EDMA_DREQ_0_1 reset 0x20001
  [23:16] DMA_EDMA_DREQ_1_IRQ_1 rw, [7:0] DMA_EDMA_DREQ_0_IRQ_0 rw
0xC7C CTRL_CORE_DMA_EDMA_DREQ_2_3 reset 0x40003
  [23:16] DMA_EDMA_DREQ_3_IRQ_3 rw, [7:0] DMA_EDMA_DREQ_2_IRQ_2 rw
0xC80 CTRL_CORE_DMA_EDMA_DREQ_4_5 reset 0x60005
  [23:16] DMA_EDMA_DREQ_5_IRQ_5 rw, [7:0] DMA_EDMA_DREQ_4_IRQ_4 rw
0xC84 CTRL_CORE_DMA_EDMA_DREQ_6_7 reset 0x80007
  [23:16] DMA_EDMA_DREQ_7_IRQ_7 rw, [7:0] DMA_EDMA_DREQ_6_IRQ_6 rw
0xC88 CTRL_CORE_DMA_EDMA_DREQ_8_9 reset 0xA0009
  [23:16] DMA_EDMA_DREQ_9_IRQ_9 rw, [7:0] DMA_EDMA_DREQ_8_IRQ_8 rw
0xC8C CTRL_CORE_DMA_EDMA_DREQ_10_11 reset 0xC000B
  [23:16] DMA_EDMA_DREQ_11_IRQ_11 rw, [7:0] DMA_EDMA_DREQ_10_IRQ_10 rw
0xC90 CTRL_CORE_DMA_EDMA_DREQ_12_13 reset 0xE000D
  [23:16] DMA_EDMA_DREQ_13_IRQ_13 rw, [7:0] DMA_EDMA_DREQ_12_IRQ_12 rw
0xC94 CTRL_CORE_DMA_EDMA_DREQ_14_15 reset 0x10000F
  [23:16] DMA_EDMA_DREQ_15_IRQ_15 rw, [7:0] DMA_EDMA_DREQ_14_IRQ_14 rw
0xC98 CTRL_CORE_DMA_EDMA_DREQ_16_17 reset 0x120011
  [23:16] DMA_EDMA_DREQ_17_IRQ_17 rw, [7:0] DMA_EDMA_DREQ_16_IRQ_16 rw
0xC9C CTRL_CORE_DMA_EDMA_DREQ_18_19 reset 0x140013
  [23:16] DMA_EDMA_DREQ_19_IRQ_19 rw, [7:0] DMA_EDMA_DREQ_18_IRQ_18 rw
0xCA0 CTRL_CORE_DMA_EDMA_DREQ_20_21 reset 0x160015
  [23:16] DMA_EDMA_DREQ_21_IRQ_21 rw, [7:0] DMA_EDMA_DREQ_20_IRQ_20 rw
0xCA4 CTRL_CORE_DMA_EDMA_DREQ_22_23 reset 0x180017
  [23:16] DMA_EDMA_DREQ_23_IRQ_23 rw, [7:0] DMA_EDMA_DREQ_22_IRQ_22 rw
0xCA8 CTRL_CORE_DMA_EDMA_DREQ_24_25 reset 0x1A0019
  [23:16] DMA_EDMA_DREQ_25_IRQ_25 rw, [7:0] DMA_EDMA_DREQ_24_IRQ_24 rw
0xCAC CTRL_CORE_DMA_EDMA_DREQ_26_27 reset 0x1C001B
  [23:16] DMA_EDMA_DREQ_27_IRQ_27 rw, [7:0] DMA_EDMA_DREQ_26_IRQ_26 rw
0xCB0 CTRL_CORE_DMA_EDMA_DREQ_28_29 reset 0x1E001D
  [23:16] DMA_EDMA_DREQ_29_IRQ_29 rw, [7:0] DMA_EDMA_DREQ_28_IRQ_28 rw
0xCB4 CTRL_CORE_DMA_EDMA_DREQ_30_31 reset 0x20001F
  [23:16] DMA_EDMA_DREQ_31_IRQ_31 rw, [7:0] DMA_EDMA_DREQ_30_IRQ_30 rw
0xCB8 CTRL_CORE_DMA_EDMA_DREQ_32_33 reset 0x220021
  [23:16] DMA_EDMA_DREQ_33_IRQ_33 rw, [7:0] DMA_EDMA_DREQ_32_IRQ_32 rw
0xCBC CTRL_CORE_DMA_EDMA_DREQ_34_35 reset 0x240023
  [23:16] DMA_EDMA_DREQ_35_IRQ_35 rw, [7:0] DMA_EDMA_DREQ_34_IRQ_34 rw
0xCC0 CTRL_CORE_DMA_EDMA_DREQ_36_37 reset 0x260025
  [23:16] DMA_EDMA_DREQ_37_IRQ_37 rw, [7:0] DMA_EDMA_DREQ_36_IRQ_36 rw
0xCC4 CTRL_CORE_DMA_EDMA_DREQ_38_39 reset 0x280027
  [23:16] DMA_EDMA_DREQ_39_IRQ_39 rw, [7:0] DMA_EDMA_DREQ_38_IRQ_38 rw
0xCC8 CTRL_CORE_DMA_EDMA_DREQ_40_41 reset 0x2A0029
  [23:16] DMA_EDMA_DREQ_41_IRQ_41 rw, [7:0] DMA_EDMA_DREQ_40_IRQ_40 rw
0xCCC CTRL_CORE_DMA_EDMA_DREQ_42_43 reset 0x2C002B
  [23:16] DMA_EDMA_DREQ_43_IRQ_43 rw, [7:0] DMA_EDMA_DREQ_42_IRQ_42 rw
0xCD0 CTRL_CORE_DMA_EDMA_DREQ_44_45 reset 0x2E002D
  [23:16] DMA_EDMA_DREQ_45_IRQ_45 rw, [7:0] DMA_EDMA_DREQ_44_IRQ_44 rw
0xCD4 CTRL_CORE_DMA_EDMA_DREQ_46_47 reset 0x30002F
  [23:16] DMA_EDMA_DREQ_47_IRQ_47 rw, [7:0] DMA_EDMA_DREQ_46_IRQ_46 rw
0xCD8 CTRL_CORE_DMA_EDMA_DREQ_48_49 reset 0x320031
  [23:16] DMA_EDMA_DREQ_49_IRQ_49 rw, [7:0] DMA_EDMA_DREQ_48_IRQ_48 rw
0xCDC CTRL_CORE_DMA_EDMA_DREQ_50_51 reset 0x340033
  [23:16] DMA_EDMA_DREQ_51_IRQ_51 rw, [7:0] DMA_EDMA_DREQ_50_IRQ_50 rw
0xCE0 CTRL_CORE_DMA_EDMA_DREQ_52_53 reset 0x360035
  [23:16] DMA_EDMA_DREQ_53_IRQ_53 rw, [7:0] DMA_EDMA_DREQ_52_IRQ_52 rw
0xCE4 CTRL_CORE_DMA_EDMA_DREQ_54_55 reset 0x380037
  [23:16] DMA_EDMA_DREQ_55_IRQ_55 rw, [7:0] DMA_EDMA_DREQ_54_IRQ_54 rw
0xCE8 CTRL_CORE_DMA_EDMA_DREQ_56_57 reset 0x3A0039
  [23:16] DMA_EDMA_DREQ_57_IRQ_57 rw, [7:0] DMA_EDMA_DREQ_56_IRQ_56 rw
0xCEC CTRL_CORE_DMA_EDMA_DREQ_58_59 reset 0x3C003B
  [23:16] DMA_EDMA_DREQ_59_IRQ_59 rw, [7:0] DMA_EDMA_DREQ_58_IRQ_58 rw
0xCF0 CTRL_CORE_DMA_EDMA_DREQ_60_61 reset 0x3E003D
  [23:16] DMA_EDMA_DREQ_61_IRQ_61 rw, [7:0] DMA_EDMA_DREQ_60_IRQ_60 rw
0xCF4 CTRL_CORE_DMA_EDMA_DREQ_62_63 reset 0x40003F
  [23:16] DMA_EDMA_DREQ_63_IRQ_63 rw, [7:0] DMA_EDMA_DREQ_62_IRQ_62 rw
0xCF8 CTRL_CORE_DMA_DSP1_DREQ_0_1 reset 0x810080
  [23:16] DMA_DSP1_DREQ_1_IRQ_1 rw, [7:0] DMA_DSP1_DREQ_0_IRQ_0 rw
0xCFC CTRL_CORE_DMA_DSP1_DREQ_2_3 reset 0x830082
  [23:16] DMA_DSP1_DREQ_3_IRQ_3 rw, [7:0] DMA_DSP1_DREQ_2_IRQ_2 rw
0xD00 CTRL_CORE_DMA_DSP1_DREQ_4_5 reset 0x850084
  [23:16] DMA_DSP1_DREQ_5_IRQ_5 rw, [7:0] DMA_DSP1_DREQ_4_IRQ_4 rw
0xD04 CTRL_CORE_DMA_DSP1_DREQ_6_7 reset 0x870086
  [23:16] DMA_DSP1_DREQ_7_IRQ_7 rw, [7:0] DMA_DSP1_DREQ_6_IRQ_6 rw
0xD08 CTRL_CORE_DMA_DSP1_DREQ_8_9 reset 0x890088
  [23:16] DMA_DSP1_DREQ_9_IRQ_9 rw, [7:0] DMA_DSP1_DREQ_8_IRQ_8 rw
0xD0C CTRL_CORE_DMA_DSP1_DREQ_10_11 reset 0x8B008A
  [23:16] DMA_DSP1_DREQ_11_IRQ_11 rw, [7:0] DMA_DSP1_DREQ_10_IRQ_10 rw
0xD10 CTRL_CORE_DMA_DSP1_DREQ_12_13 reset 0x8D008C
  [23:16] DMA_DSP1_DREQ_13_IRQ_13 rw, [7:0] DMA_DSP1_DREQ_12_IRQ_12 rw
0xD14 CTRL_CORE_DMA_DSP1_DREQ_14_15 reset 0x8F008E
  [23:16] DMA_DSP1_DREQ_15_IRQ_15 rw, [7:0] DMA_DSP1_DREQ_14_IRQ_14 rw
0xD18 CTRL_CORE_DMA_DSP1_DREQ_16_17 reset 0x9B009A
  [23:16] DMA_DSP1_DREQ_17_IRQ_17 rw, [7:0] DMA_DSP1_DREQ_16_IRQ_16 rw
0xD1C CTRL_CORE_DMA_DSP1_DREQ_18_19 reset 0x9D009C
  [23:16] DMA_DSP1_DREQ_19_IRQ_19 rw, [7:0] DMA_DSP1_DREQ_18_IRQ_18 rw
0xD20 CTRL_CORE_DMA_DSP2_DREQ_0_1 reset 0x810080
  [23:16] DMA_DSP2_DREQ_1_IRQ_1 rw, [7:0] DMA_DSP2_DREQ_0_IRQ_0 rw
0xD24 CTRL_CORE_DMA_DSP2_DREQ_2_3 reset 0x830082
  [23:16] DMA_DSP2_DREQ_3_IRQ_3 rw, [7:0] DMA_DSP2_DREQ_2_IRQ_2 rw
0xD28 CTRL_CORE_DMA_DSP2_DREQ_4_5 reset 0x850084
  [23:16] DMA_DSP2_DREQ_5_IRQ_5 rw, [7:0] DMA_DSP2_DREQ_4_IRQ_4 rw
0xD2C CTRL_CORE_DMA_DSP2_DREQ_6_7 reset 0x870086
  [23:16] DMA_DSP2_DREQ_7_IRQ_7 rw, [7:0] DMA_DSP2_DREQ_6_IRQ_6 rw
0xD30 CTRL_CORE_DMA_DSP2_DREQ_8_9 reset 0x890088
  [23:16] DMA_DSP2_DREQ_9_IRQ_9 rw, [7:0] DMA_DSP2_DREQ_8_IRQ_8 rw
0xD34 CTRL_CORE_DMA_DSP2_DREQ_10_11 reset 0x8B008A
  [23:16] DMA_DSP2_DREQ_11_IRQ_11 rw, [7:0] DMA_DSP2_DREQ_10_IRQ_10 rw
0xD38 CTRL_CORE_DMA_DSP2_DREQ_12_13 reset 0x8D008C
  [23:16] DMA_DSP2_DREQ_13_IRQ_13 rw, [7:0] DMA_DSP2_DREQ_12_IRQ_12 rw
0xD3C CTRL_CORE_DMA_DSP2_DREQ_14_15 reset 0x8F008E
  [23:16] DMA_DSP2_DREQ_15_IRQ_15 rw, [7:0] DMA_DSP2_DREQ_14_IRQ_14 rw
0xD40 CTRL_CORE_DMA_DSP2_DREQ_16_17 reset 0x9B009A
  [23:16] DMA_DSP2_DREQ_17_IRQ_17 rw, [7:0] DMA_DSP2_DREQ_16_IRQ_16 rw
0xD44 CTRL_CORE_DMA_DSP2_DREQ_18_19 reset 0x9D009C
  [23:16] DMA_DSP2_DREQ_19_IRQ_19 rw, [7:0] DMA_DSP2_DREQ_18_IRQ_18 rw
0xD54 CTRL_CORE_ESM_GROUP1_0 reset 0xEA
  [8:0] ESM_GROUP1_0_IRQ_0 rw
0xD58 CTRL_CORE_ESM_GROUP1_1 reset 0x19D
  [8:0] ESM_GROUP1_1_IRQ_1 rw
0xD5C CTRL_CORE_ESM_GROUP1_2 reset 0x19F
  [8:0] ESM_GROUP1_2_IRQ_2 rw
0xD60 CTRL_CORE_ESM_GROUP1_3 reset 0x4
  [7:0] ESM_GROUP1_3_DMA_3 rw
0xE30 CTRL_CORE_CONTROL_DDRCACH1_0 rw reset 0x4A4A4A4A — ddrcaCH1 control
  [31:29] DDRCH1_PART0_I — PART0 Impedence control I[2:0] 0x0: Imp80 0x1: Imp60 0x2: Imp48 0x3: Imp40 0x4: Imp34 0x5: Reserved 0x6: Reserved 0x7: Reserved
  [28:26] DDRCH1_PART0_SR — PART0 Slew Rate control SR[2:0]. All 8 values are valid. 0x0: Fastest .... 0x7: Slowest
  [25:24] DDRCH1_PART0_WD — PART0 Weak driver control WD[1:0] -For single-ended operation: 0x0: Pull logic is disabled 0x1: Pull-up selected 0x2: Pull-down selected 0x3: Maintain the previous output value -For differential pair operation: 0x0: Pull logic is disabled 0x1: Pull-up selected for padp, pull-down selected for padn 0x2: Pull-down selected for padp, pull-up selected for padn 0x3: Maintain the previous output value
  [23:21] DDRCH1_PART5A_I — PART5A Impedence control I[2:0] 0x0: Imp80 0x1: Imp60 0x2: Imp48 0x3: Imp40 0x4: Imp34 0x5: Reserved 0x6: Reserved 0x7: Reserved
  [20:18] DDRCH1_PART5A_SR — PART5A Slew Rate control SR[2:0]. All 8 values are valid. 0x0: Fastest .... 0x7: Slowest
  [17:16] DDRCH1_PART5A_WD — PART5A Weak driver control WD[1:0] -For single-ended operation: 0x0: Pull logic is disabled 0x1: Pull-up selected 0x2: Pull-down selected 0x3: Maintain the previous output value -For differential pair operation: 0x0: Pull logic is disabled 0x1: Pull-up selected for padp, pull-down selected for padn 0x2: Pull-down selected for padp, pull-up selected for padn 0x3: Maintain the previous output value
  [15:13] DDRCH1_PART5B_I — PART5B Impedence control I[2:0] 0x0: Imp80 0x1: Imp60 0x2: Imp48 0x3: Imp40 0x4: Imp34 0x5: Reserved 0x6: Reserved 0x7: Reserved
  [12:10] DDRCH1_PART5B_SR — PART5B Slew Rate control SR[2:0]. All 8 values are valid. 0x0: Fastest .... 0x7: Slowest
  [9:8] DDRCH1_PART5B_WD — PART5B Weak driver control WD[1:0] -For single-ended operation: 0x0: Pull logic is disabled 0x1: Pull-up selected 0x2: Pull-down selected 0x3: Maintain the previous output value -For differential pair operation: 0x0: Pull logic is disabled 0x1: Pull-up selected for padp, pull-down selected for padn 0x2: Pull-down selected for padp, pull-up selected for padn 0x3: Maintain the previous output value
  [7:5] DDRCH1_PART6_I — PART6 Impedence control I[2:0] 0x0: Imp80 0x1: Imp60 0x2: Imp48 0x3: Imp40 0x4: Imp34 0x5: Reserved 0x6: Reserved 0x7: Reserved
  [4:2] DDRCH1_PART6_SR — PART6 Slew Rate control SR[2:0]. All 8 values are valid. 0x0: Fastest .... 0x7: Slowest
  [1:0] DDRCH1_PART6_WD — PART6 Weak driver control WD[1:0] -For single-ended operation: 0x0: Pull logic is disabled 0x1: Pull-up selected 0x2: Pull-down selected 0x3: Maintain the previous output value -For differential pair operation: 0x0: Pull logic is disabled 0x1: Pull-up selected for padp, pull-down selected for padn 0x2: Pull-down selected for padp, pull-up selected for padn 0x3: Maintain the previous output value
0xE38 CTRL_CORE_CONTROL_DDRCH1_0 rw reset 0x4A4A4A4A — DDRCH1 control 0
  [31:29] DDRCH1_PART1A_I — PART1A Impedence control I[2:0] 0x0: Imp80 0x1: Imp60 0x2: Imp48 0x3: Imp40 0x4: Imp34 0x5: Reserved 0x6: Reserved 0x7: Reserved
  [28:26] DDRCH1_PART1A_SR — PART1A Slew Rate control SR[2:0]. All 8 values are valid. 0x0: Fastest .... 0x7: Slowest
  [25:24] DDRCH1_PART1A_WD — PART1A Weak driver control WD[1:0] -For single-ended operation: 0x0: Pull logic is disabled 0x1: Pull-up selected 0x2: Pull-down selected 0x3: Maintain the previous output value -For differential pair operation: 0x0: Pull logic is disabled 0x1: Pull-up selected for padp, pull-down selected for padn 0x2: Pull-down selected for padp, pull-up selected for padn 0x3: Maintain the previous output value
  [23:21] DDRCH1_PART1B_I — PART1B Impedence control I[2:0] 0x0: Imp80 0x1: Imp60 0x2: Imp48 0x3: Imp40 0x4: Imp34 0x5: Reserved 0x6: Reserved 0x7: Reserved
  [20:18] DDRCH1_PART1B_SR — PART1B Slew Rate control SR[2:0]. All 8 values are valid. 0x0: Fastest .... 0x7: Slowest
  [17:16] DDRCH1_PART1B_WD — PART1B Weak driver control WD[1:0] -For single-ended operation: 0x0: Pull logic is disabled 0x1: Pull-up selected 0x2: Pull-down selected 0x3: Maintain the previous output value -For differential pair operation: 0x0: Pull logic is disabled 0x1: Pull-up selected for padp, pull-down selected for padn 0x2: Pull-down selected for padp, pull-up selected for padn 0x3: Maintain the previous output value
  [15:13] DDRCH1_PART2A_I — PART2A Impedence control I[2:0] 0x0: Imp80 0x1: Imp60 0x2: Imp48 0x3: Imp40 0x4: Imp34 0x5: Reserved 0x6: Reserved 0x7: Reserved
  [12:10] DDRCH1_PART2A_SR — PART2A Slew Rate control SR[2:0]. All 8 values are valid. 0x0: Fastest .... 0x7: Slowest
  [9:8] DDRCH1_PART2A_WD — PART2A Weak driver control WD[1:0] -For single-ended operation: 0x0: Pull logic is disabled 0x1: Pull-up selected 0x2: Pull-down selected 0x3: Maintain the previous output value -For differential pair operation: 0x0: Pull logic is disabled 0x1: Pull-up selected for padp, pull-down selected for padn 0x2: Pull-down selected for padp, pull-up selected for padn 0x3: Maintain the previous output value
  [7:5] DDRCH1_PART2B_I — PART2B Impedence control I[2:0] 0x0: Imp80 0x1: Imp60 0x2: Imp48 0x3: Imp40 0x4: Imp34 0x5: Reserved 0x6: Reserved 0x7: Reserved
  [4:2] DDRCH1_PART2B_SR — PART2B Slew Rate control SR[2:0]. All 8 values are valid. 0x0: Fastest .... 0x7: Slowest
  [1:0] DDRCH1_PART2B_WD — PART2B Weak driver control WD[1:0] -For single-ended operation: 0x0: Pull logic is disabled 0x1: Pull-up selected 0x2: Pull-down selected 0x3: Maintain the previous output value -For differential pair operation: 0x0: Pull logic is disabled 0x1: Pull-up selected for padp, pull-down selected for padn 0x2: Pull-down selected for padp, pull-up selected for padn 0x3: Maintain the previous output value
0xE3C CTRL_CORE_CONTROL_DDRCH1_1 rw reset 0x4A4A4A4A — DDRCH1 control 1
  [31:29] DDRCH1_PART3A_I — PART3A Impedence control I[2:0] 0x0: Imp80 0x1: Imp60 0x2: Imp48 0x3: Imp40 0x4: Imp34 0x5: Reserved 0x6: Reserved 0x7: Reserved
  [28:26] DDRCH1_PART3A_SR — PART3A Slew Rate control SR[2:0]. All 8 values are valid. 0x0: Fastest .... 0x7: Slowest
  [25:24] DDRCH1_PART3A_WD — PART3A Weak driver control WD[1:0] -For single-ended operation: 0x0: Pull logic is disabled 0x1: Pull-up selected 0x2: Pull-down selected 0x3: Maintain the previous output value -For differential pair operation: 0x0: Pull logic is disabled 0x1: Pull-up selected for padp, pull-down selected for padn 0x2: Pull-down selected for padp, pull-up selected for padn 0x3: Maintain the previous output value
  [23:21] DDRCH1_PART3B_I — PART3B Impedence control I[2:0] 0x0: Imp80 0x1: Imp60 0x2: Imp48 0x3: Imp40 0x4: Imp34 0x5: Reserved 0x6: Reserved 0x7: Reserved
  [20:18] DDRCH1_PART3B_SR — PART3B Slew Rate control SR[2:0]. All 8 values are valid. 0x0: Fastest .... 0x7: Slowest
  [17:16] DDRCH1_PART3B_WD — PART3B Weak driver control WD[1:0] -For single-ended operation: 0x0: Pull logic is disabled 0x1: Pull-up selected 0x2: Pull-down selected 0x3: Maintain the previous output value -For differential pair operation: 0x0: Pull logic is disabled 0x1: Pull-up selected for padp, pull-down selected for padn 0x2: Pull-down selected for padp, pull-up selected for padn 0x3: Maintain the previous output value
  [15:13] DDRCH1_PART4A_I — PART4A Impedence control I[2:0] 0x0: Imp80 0x1: Imp60 0x2: Imp48 0x3: Imp40 0x4: Imp34 0x5: Reserved 0x6: Reserved 0x7: Reserved
  [12:10] DDRCH1_PART4A_SR — PART4A Slew Rate control SR[2:0]. All 8 values are valid. 0x0: Fastest .... 0x7: Slowest
  [9:8] DDRCH1_PART4A_WD — PART4A Weak driver control WD[1:0] -For single-ended operation: 0x0: Pull logic is disabled 0x1: Pull-up selected 0x2: Pull-down selected 0x3: Maintain the previous output value -For differential pair operation: 0x0: Pull logic is disabled 0x1: Pull-up selected for padp, pull-down selected for padn 0x2: Pull-down selected for padp, pull-up selected for padn 0x3: Maintain the previous output value
  [7:5] DDRCH1_PART4B_I — PART4B Impedence control I[2:0] 0x0: Imp80 0x1: Imp60 0x2: Imp48 0x3: Imp40 0x4: Imp34 0x5: Reserved 0x6: Reserved 0x7: Reserved
  [4:2] DDRCH1_PART4B_SR — PART4B Slew Rate control SR[2:0]. All 8 values are valid. 0x0: Fastest .... 0x7: Slowest
  [1:0] DDRCH1_PART4B_WD — PART4B Weak driver control WD[1:0] -For single-ended operation: 0x0: Pull logic is disabled 0x1: Pull-up selected 0x2: Pull-down selected 0x3: Maintain the previous output value -For differential pair operation: 0x0: Pull logic is disabled 0x1: Pull-up selected for padp, pull-down selected for padn 0x2: Pull-down selected for padp, pull-up selected for padn 0x3: Maintain the previous output value
0xE48 CTRL_CORE_CONTROL_DDRCH1_2 reset 0x4A4A00
  [23:21] DDRCH1_PART7A_I rw — PART7A Impedence control I[2:0] 0x0: Imp80 0x1: Imp60 0x2: Imp48 0x3: Imp40 0x4: Imp34 0x5: Reserved 0x6: Reserved 0x7: Reserved
  [20:18] DDRCH1_PART7A_SR rw — PART7A Slew Rate control SR[2:0]. All 8 values are valid. 0x0: Fastest .... 0x7: Slowest
  [17:16] DDRCH1_PART7A_WD rw — PART7A Weak driver control WD[1:0] -For single-ended operation: 0x0: Pull logic is disabled 0x1: Pull-up selected 0x2: Pull-down selected 0x3: Maintain the previous output value -For differential pair operation: 0x0: Pull logic is disabled 0x1: Pull-up selected for padp, pull-down selected for padn 0x2: Pull-down selected for padp, pull-up selected for padn 0x3: Maintain the previous output value
  [15:13] DDRCH1_PART7B_I rw — PART7B Impedence control I[2:0] 0x0: Imp80 0x1: Imp60 0x2: Imp48 0x3: Imp40 0x4: Imp34 0x5: Reserved 0x6: Reserved 0x7: Reserved
  [12:10] DDRCH1_PART7B_SR rw — PART7B Slew Rate control SR[2:0]. All 8 values are valid. 0x0: Fastest .... 0x7: Slowest
  [9:8] DDRCH1_PART7B_WD rw — PART7B Weak driver control WD[1:0] -For single-ended operation: 0x0: Pull logic is disabled 0x1: Pull-up selected 0x2: Pull-down selected 0x3: Maintain the previous output value -For differential pair operation: 0x0: Pull logic is disabled 0x1: Pull-up selected for padp, pull-down selected for padn 0x2: Pull-down selected for padp, pull-up selected for padn 0x3: Maintain the previous output value
0xE50 CTRL_CORE_CONTROL_DDRIO_0 reset 0x9CE60
  [all] fields
    0=DISABLE (Disabled); 1=ENABLE (Enabled)
  [19] DDRCH1_VREF_DQ0_INT_CCAP0 rw — Selection for coupling cap connection
  [18] DDRCH1_VREF_DQ0_INT_CCAP1 rw — Selection for coupling cap connection
  [17] DDRCH1_VREF_DQ0_INT_TAP0 rw — Selection for internal reference voltage drive
  [16] DDRCH1_VREF_DQ0_INT_TAP1 rw — Selection for internal reference voltage drive
  [15] DDRCH1_VREF_DQ0_INT_EN rw — Enable
  [14] DDRCH1_VREF_DQ1_INT_CCAP0 rw — Selection for coupling cap connection
  [13] DDRCH1_VREF_DQ1_INT_CCAP1 rw — Selection for coupling cap connection
  [12] DDRCH1_VREF_DQ1_INT_TAP0 rw — Selection for internal reference voltage drive
  [11] DDRCH1_VREF_DQ1_INT_TAP1 rw — Selection for internal reference voltage drive
  [10] DDRCH1_VREF_DQ1_INT_EN rw — Enable
0x1000 CTRL_CORE_HWOBS_FINAL_MUX_SEL rw — This register controls the final multiplexor which selects whether CORE or WKUP observable signals are mapped to the final observability bus, that is obs[31:0] bus.
  [31:0] SELECT — Each bit is associated with one observability signal line. Bit 31 selects between CORE and WKUP signal for obs31 line and bit 0 does the same for obs0 line. The same logic applies for all other bits.
    0=WKUP_signal_selected; 1=CORE_signal_selected
0x100C CTRL_CORE_CONF_DEBUG_SEL_TST_0 — This register is used to select an observable signal for CORE observability line 0.
  [5:0] MODE rw — Selects one of the following signals to be available on CORE observability line 0. This signal can then be mapped to obs0 line throughCTRL_CORE_HWOBS_FINAL_MUX_SEL[0] bit. Values not shown are reserved.
    7=hwobs_debug_dss(0); 11=hwobs_dsshdcpducatidisable; 14=hwobs_emif1_prcm_deviceoff_wkup_core_rstactst; 18=hwobs_debug_debugss(0); 21=hwobs_emif1_phy_reg_status_phy_ctrl_dll_lock(0); 22=hwobs_emif1_phy_reg_rdlvl_dqs_ratio_byte0_rank0(0); 23=hwobs_emif1_phy_reg_rdlvl_dqs_ratio_byte0_rank1(0); 24=hwobs_emif1_phy_reg_status_phy_ctrl_dll_lock(1); 30=hwobs_eve1_eve_dbgout[23]; 34=hwobs_dsp1_Turing_hw_dbgout_[31]; 35=hwobs_dsp2_Turing_hw_dbgout_[31]; 38=hwobs_vip1_outmux_testport[0]; 42=hwobs_debug_prm(0); 43=hwobs_debug_cm_core_aon(0); 44=hwobs_int_iss(0); 45=hwobs_int_iss(32); 46=func_spare_out[0]; 47=dft_test_pad_i[0]; 48=dft_test_pad_o[0]
0x1010 CTRL_CORE_CONF_DEBUG_SEL_TST_1 — This register is used to select an observable signal for CORE observability line 1.
  [5:0] MODE rw — Selects one of the following signals to be available on CORE observability line 1. This signal can then be mapped to obs1 line throughCTRL_CORE_HWOBS_FINAL_MUX_SEL[1] bit. Values not shown are reserved.
    7=hwobs_debug_dss(1); 9=hwobs_dspdpll_freqlock; 11=hwobs_dsshdcpsecurity_violation; 12=hwobs_ddrdpll_freqlock; 14=hwobs_emif1_pwr_sidlereq; 18=hwobs_debug_debugss(1); 21=hwobs_emif1_phy_reg_status_phy_ctrl_dll_lock(1); 22=hwobs_emif1_phy_reg_rdlvl_dqs_ratio_byte0_rank0(1); 23=hwobs_emif1_phy_reg_rdlvl_dqs_ratio_byte0_rank1(1); 24=hwobs_emif1_phy_reg_status_phy_ctrl_dll_lock(0); 30=hwobs_eve1_eve_dbgout[22]; 34=hwobs_dsp1_Turing_hw_dbgout_[30]; 35=hwobs_dsp2_Turing_hw_dbgout_[30]; 38=hwobs_vip1_outmux_testport[1]; 42=hwobs_debug_prm(1); 43=hwobs_debug_cm_core_aon(1); 44=hwobs_int_iss(1); 45=hwobs_int_iss(33); 46=func_spare_out[1]; 47=dft_test_pad_i[1]; 48=dft_test_pad_o[1]
